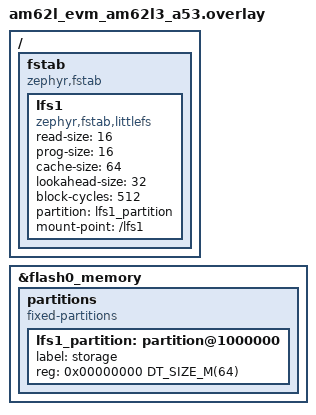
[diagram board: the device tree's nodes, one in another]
/*
 * SPDX-FileCopyrightText: 2026 Texas Instruments Incorporated
 *
 * SPDX-License-Identifier: Apache-2.0
 */

/ {
	fstab {
		compatible = "zephyr,fstab";

		lfs1: lfs1 {
			compatible = "zephyr,fstab,littlefs";
			read-size = <16>;
			prog-size = <16>;
			cache-size = <64>;
			lookahead-size = <32>;
			block-cycles = <512>;
			partition = <&lfs1_partition>;
			mount-point = "/lfs1";
		};
	};
};

&flash0_memory {
	partitions {
		compatible = "fixed-partitions";
		#address-cells = <1>;
		#size-cells = <1>;

		lfs1_partition: partition@1000000 {
			label = "storage";
			reg = <0x00000000 DT_SIZE_M(64)>;
		};
	};
};
